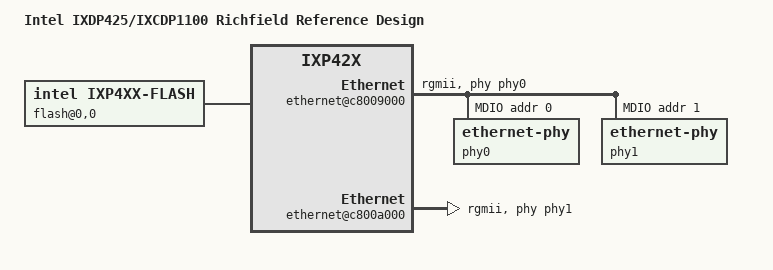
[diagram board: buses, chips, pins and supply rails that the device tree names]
/dts-v1/;
#include "intel-ixp42x.dtsi"
#include "intel-ixp4xx-reference-design.dtsi"
#include <dt-bindings/input/input.h>
/ {
	model = "Intel IXDP425/IXCDP1100 Richfield Reference Design";
	compatible = "intel,ixdp425", "intel,ixp42x";
	#address-cells = <1>;
	#size-cells = <1>;
	soc {
		bus@c4000000 {
			flash@0,0 {
				compatible = "intel,ixp4xx-flash", "cfi-flash";
				bank-width = <2>;
				intel,ixp4xx-eb-write-enable = <1>;
				reg = <0 0x00000000 0x1000000>;
				partitions {
					compatible = "redboot-fis";
					fis-index-block = <0x7f>;
				};
			};
		};
		ethernet@c8009000 {
			status = "okay";
			queue-rx = <&qmgr 3>;
			queue-txready = <&qmgr 20>;
			phy-mode = "rgmii";
			phy-handle = <&phy0>;
			mdio {
				#address-cells = <1>;
				#size-cells = <0>;
				phy0: ethernet-phy@0 {
					reg = <0>;
				};
				phy1: ethernet-phy@1 {
					reg = <1>;
				};
			};
		};
		ethernet@c800a000 {
			status = "okay";
			queue-rx = <&qmgr 4>;
			queue-txready = <&qmgr 21>;
			phy-mode = "rgmii";
			phy-handle = <&phy1>;
		};
	};
};
